# ESP32-P4 register map
Vendor: ESPRESSIF SYSTEMS (SHANGHAI) CO., LTD.; Series: ESP32 P-Series; File version: 3
CPU: RV32IMAFC r0p0, little endian, no MPU, FPU, 0 interrupt priority bits
Address unit: 32 bits
Registers are 32-bit, read-write, reset 0x0 unless marked. A register's access mark holds for its fields unless they carry their own. Offsets are from the block's base; [hi:lo] are bit positions; {n}, {i} and the like mark numbered series.

## RSA — RSA (Rivest Shamir Adleman) Accelerator
Base 0x50092000
{0x0+4i} M_MEM[{i}] (i=0..127) wo — Represents M
{0x200+4i} Z_MEM[{i}] (i=0..127) — Represents Z
{0x400+4i} Y_MEM[{i}] (i=0..127) wo — Represents Y
{0x600+4i} X_MEM[{i}] (i=0..127) wo — Represents X
0x800 M_PRIME — Represents M'
0x804 MODE — Configures RSA length
  [6:0] MODE — Configures the RSA length.
0x808 QUERY_CLEAN ro — RSA initialization status
  [0] QUERY_CLEAN — Represents whether or not the RSA memory completes initialization.\\ 0: Not complete\\ 1: Completed\\
0x80C SET_START_MODEXP wo — Starts modular exponentiation
  [0] SET_START_MODEXP — Configures whether or not to starts the modular exponentiation. \\ 0: No effect\\ 1: Start\\
0x810 SET_START_MODMULT wo — Starts modular multiplication
  [0] SET_START_MODMULT — Configures whether or not to start the modular multiplication.\\ 0: No effect\\ 1: Start\\
0x814 SET_START_MULT wo — Starts multiplication
  [0] SET_START_MULT — Configures whether or not to start the multiplication.\\ 0: No effect\\ 1: Start\\
0x818 QUERY_IDLE ro — Represents the RSA status
  [0] QUERY_IDLE — Represents the RSA status.\\ 0: Busy\\ 1: Idle\\
0x81C INT_CLR wo — Clears RSA interrupt
  [0] INT_CLR — Write 1 to clear the RSA interrupt.
0x820 CONSTANT_TIME reset 0x1 — Configures the constant_time option
  [0] CONSTANT_TIME — Configures the constant_time option. \\ 0: Acceleration\\ 1: No acceleration (default)\\
0x824 SEARCH_ENABLE — Configures the search option
  [0] SEARCH_ENABLE — Configures the search option. \\ 0: No acceleration (default)\\ 1: Acceleration\\ This option should be used together with RSA_SEARCH_POS_REG.
0x828 SEARCH_POS — Configures the search position
  [11:0] SEARCH_POS — Configures the starting address to start search. This field should be used together with RSA_SEARCH_ENABLE_REG. The field is only valid when RSA_SEARCH_ENABLE is high.
0x82C INT_ENA — Enables the RSA interrupt
  [0] INT_ENA — Write 1 to enable the RSA interrupt.
0x830 DATE reset 0x20200618 — Version control register
  [29:0] DATE — Version control register.

## LP_TIMER — Low-power Timer
Base 0x50112000
0x00 TAR0_LOW — need_des
  [31:0] MAIN_TIMER_TAR_LOW0
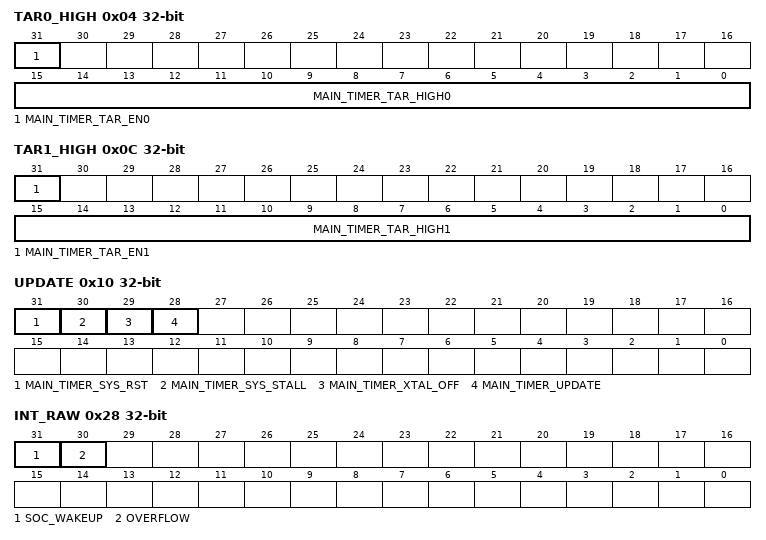
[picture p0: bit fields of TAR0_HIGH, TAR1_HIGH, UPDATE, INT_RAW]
0x04 TAR0_HIGH access per field — need_des
  [31] MAIN_TIMER_TAR_EN0 wo — need_des
  [15:0] MAIN_TIMER_TAR_HIGH0 rw — need_des
0x08 TAR1_LOW — need_des
  [31:0] MAIN_TIMER_TAR_LOW1
0x0C TAR1_HIGH access per field — need_des
  [31] MAIN_TIMER_TAR_EN1 wo — need_des
  [15:0] MAIN_TIMER_TAR_HIGH1 rw — need_des
0x10 UPDATE access per field — need_des
  [31] MAIN_TIMER_SYS_RST rw — need_des
  [30] MAIN_TIMER_SYS_STALL rw — need_des
  [29] MAIN_TIMER_XTAL_OFF rw — need_des
  [28] MAIN_TIMER_UPDATE wo — need_des
0x14 MAIN_BUF0_LOW ro — need_des
  [31:0] MAIN_TIMER_BUF0_LOW
0x18 MAIN_BUF0_HIGH ro — need_des
  [15:0] MAIN_TIMER_BUF0_HIGH
0x1C MAIN_BUF1_LOW ro — need_des
  [31:0] MAIN_TIMER_BUF1_LOW
0x20 MAIN_BUF1_HIGH ro — need_des
  [15:0] MAIN_TIMER_BUF1_HIGH
0x24 MAIN_OVERFLOW wo — need_des
  [31] MAIN_TIMER_ALARM_LOAD
0x28 INT_RAW — need_des
  [31] SOC_WAKEUP — need_des
  [30] OVERFLOW — need_des
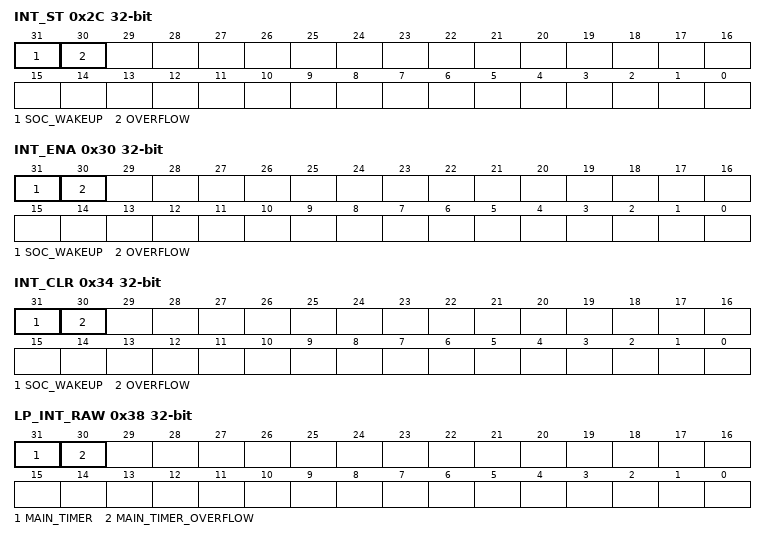
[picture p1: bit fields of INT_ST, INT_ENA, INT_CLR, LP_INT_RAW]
0x2C INT_ST ro — need_des
  [31] SOC_WAKEUP — need_des
  [30] OVERFLOW — need_des
0x30 INT_ENA — need_des
  [31] SOC_WAKEUP — need_des
  [30] OVERFLOW — need_des
0x34 INT_CLR wo — need_des
  [31] SOC_WAKEUP write-1-clears — need_des
  [30] OVERFLOW write-1-clears — need_des
0x38 LP_INT_RAW — need_des
  [31] MAIN_TIMER — need_des
  [30] MAIN_TIMER_OVERFLOW — need_des
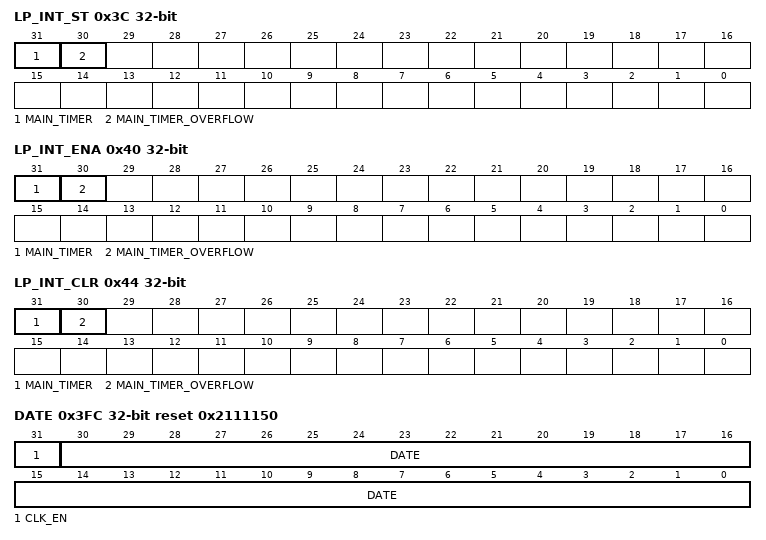
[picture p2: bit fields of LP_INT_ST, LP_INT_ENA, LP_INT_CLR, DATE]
0x3C LP_INT_ST ro — need_des
  [31] MAIN_TIMER — need_des
  [30] MAIN_TIMER_OVERFLOW — need_des
0x40 LP_INT_ENA — need_des
  [31] MAIN_TIMER — need_des
  [30] MAIN_TIMER_OVERFLOW — need_des
0x44 LP_INT_CLR wo — need_des
  [31] MAIN_TIMER write-1-clears — need_des
  [30] MAIN_TIMER_OVERFLOW write-1-clears — need_des
0x3FC DATE reset 0x2111150 — need_des
  [31] CLK_EN — need_des
  [30:0] DATE — need_des
